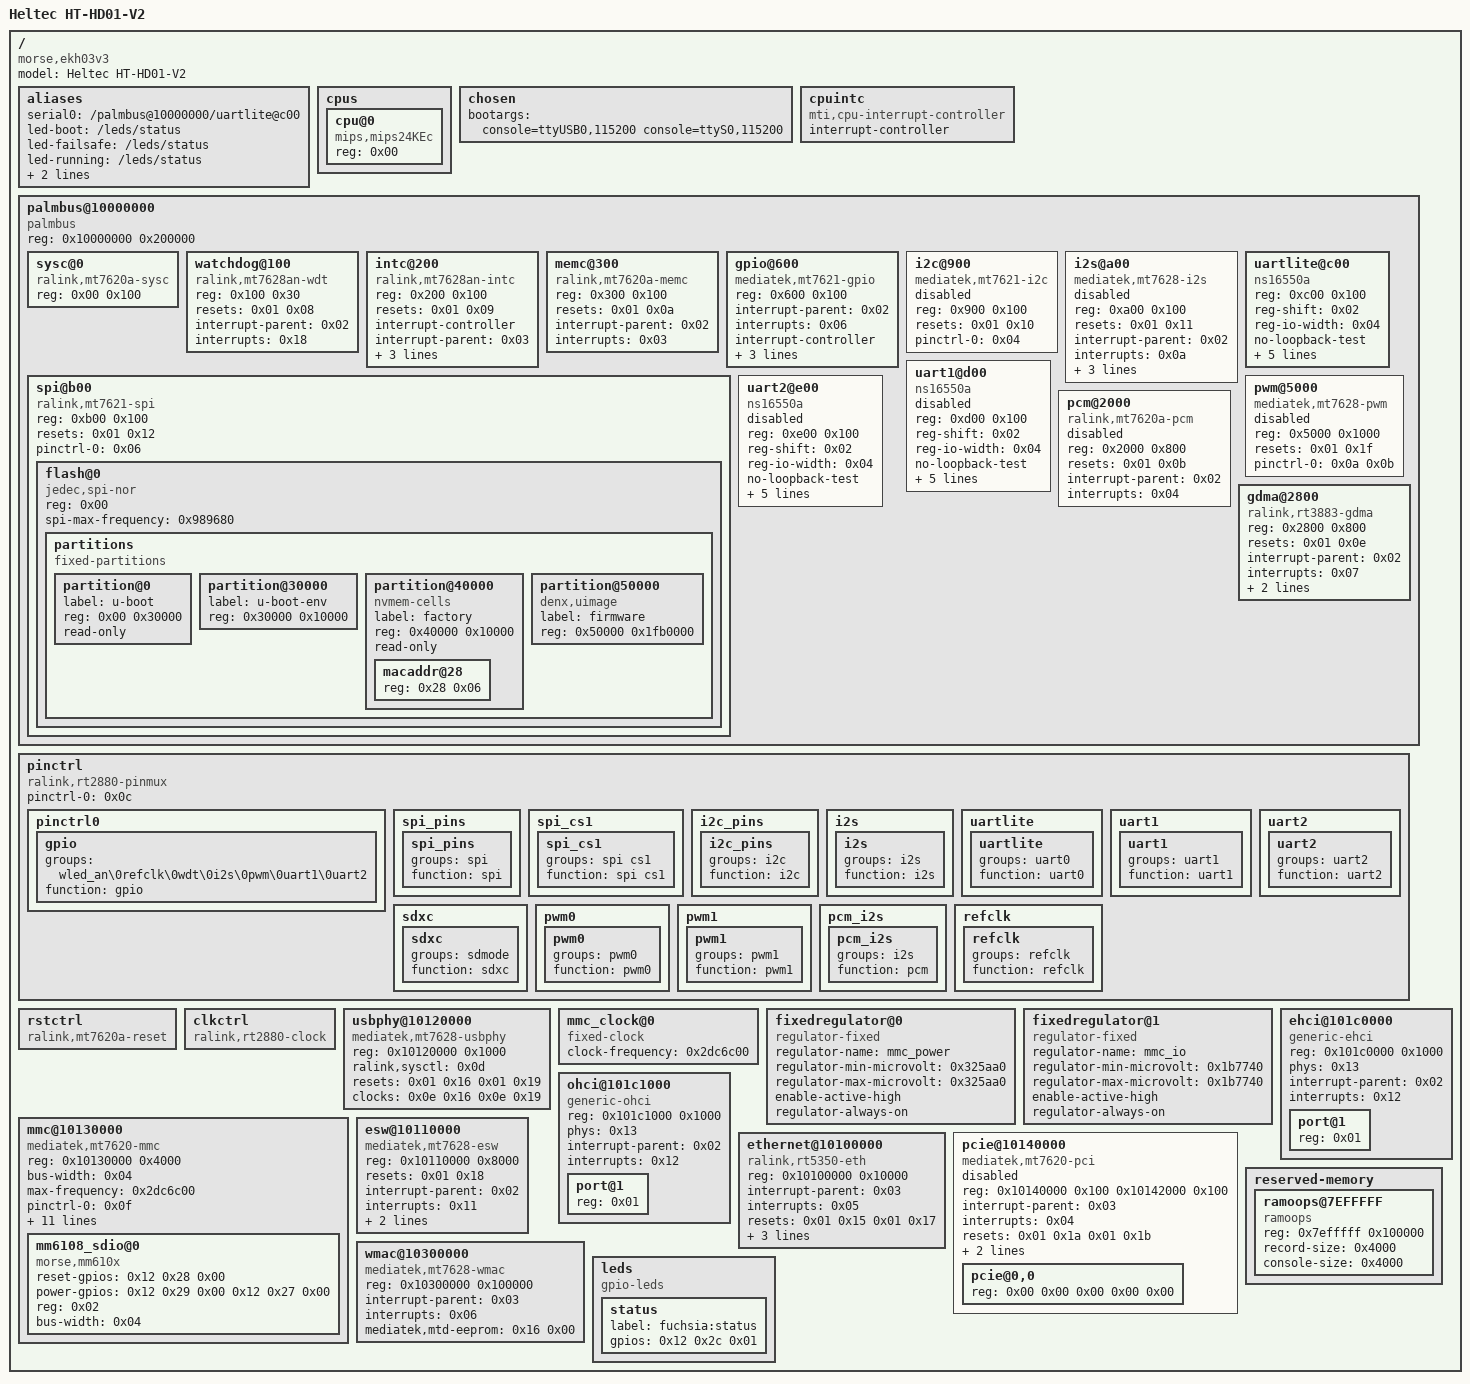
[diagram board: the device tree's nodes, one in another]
/dts-v1/;

/ {
	#address-cells = <0x01>;
	#size-cells = <0x01>;
	compatible = "morse,ekh03v3\0mediatek,mt7628an-soc";
	model = "Heltec HT-HD01-V2";

	aliases {
		serial0 = "/palmbus@10000000/uartlite@c00";
		led-boot = "/leds/status";
		led-failsafe = "/leds/status";
		led-running = "/leds/status";
		led-upgrade = "/leds/status";
		label-mac-device = "/wmac@10300000";
	};

	cpus {
		#address-cells = <0x01>;
		#size-cells = <0x00>;

		cpu@0 {
			compatible = "mips,mips24KEc";
			reg = <0x00>;
		};
	};

	chosen {
		bootargs = "console=ttyUSB0,115200 console=ttyS0,115200";
	};

	cpuintc {
		#address-cells = <0x00>;
		#interrupt-cells = <0x01>;
		interrupt-controller;
		compatible = "mti,cpu-interrupt-controller";
		phandle = <0x03>;
	};

	palmbus@10000000 {
		compatible = "palmbus";
		reg = <0x10000000 0x200000>;
		ranges = <0x00 0x10000000 0x1fffff>;
		#address-cells = <0x01>;
		#size-cells = <0x01>;

		sysc@0 {
			compatible = "ralink,mt7620a-sysc\0syscon";
			reg = <0x00 0x100>;
			phandle = <0x0d>;
		};

		watchdog@100 {
			compatible = "ralink,mt7628an-wdt\0mediatek,mt7621-wdt";
			reg = <0x100 0x30>;
			resets = <0x01 0x08>;
			reset-names = "wdt";
			interrupt-parent = <0x02>;
			interrupts = <0x18>;
		};

		intc@200 {
			compatible = "ralink,mt7628an-intc\0ralink,rt2880-intc";
			reg = <0x200 0x100>;
			resets = <0x01 0x09>;
			reset-names = "intc";
			interrupt-controller;
			#interrupt-cells = <0x01>;
			interrupt-parent = <0x03>;
			interrupts = <0x02>;
			ralink,intc-registers = <0x9c 0xa0 0x6c 0xa4 0x80 0x78>;
			phandle = <0x02>;
		};

		memc@300 {
			compatible = "ralink,mt7620a-memc\0ralink,rt3050-memc";
			reg = <0x300 0x100>;
			resets = <0x01 0x0a>;
			reset-names = "mc";
			interrupt-parent = <0x02>;
			interrupts = <0x03>;
		};

		gpio@600 {
			compatible = "mediatek,mt7621-gpio";
			reg = <0x600 0x100>;
			interrupt-parent = <0x02>;
			interrupts = <0x06>;
			#interrupt-cells = <0x02>;
			interrupt-controller;
			gpio-controller;
			#gpio-cells = <0x02>;
			gpio-line-names = "I2S_SDI\0I2S_SDO\0I2S_WS\0I2S_CLK\0I2C_SCLK\0I2C_SD\0SPI_CS1\0SPI_CLK\0SPI_MOSI\0SPI_MISO\0SPI_CS0\0\0UART_TXD0\0UART_RXD0\0MDI_TP_P1\0MDI_TN_P1\0MDI_RP_P1\0MDI_RN_P1\0MDI_RP_P2\0MDI_RN_P2\0MDI_TP_P2\0MDI_TN_P2\0MDI_TP_P3\0MDI_TN_P3\0MDI_RP_P3\0MDI_RN_P3\0MDI_RP_P4\0MDI_RN_P4\0MDI_TP_P4\0MDI_TN_P4\0\0\0\0\0\0\0PERST_N\0REF_CLKO\0WDT_RST_N\0MM_BUSY\0MM_RESET\0MM_WAKE\0EPHY_LED1_N_JTDI\0EPHY_LED0_N_JTDO\0WLED_N\0UART_TXD1\0UART_RXD1\0\0\0\0\0\0\0\0\0\0\0\0\0\0\0\0\0\0\0\0\0\0\0\0\0\0\0\0\0\0\0\0\0\0\0\0\0\0\0\0\0\0\0\0\0\0\0\0\0";
			status = "okay";
			phandle = <0x12>;
		};

		i2c@900 {
			compatible = "mediatek,mt7621-i2c";
			reg = <0x900 0x100>;
			resets = <0x01 0x10>;
			reset-names = "i2c";
			#address-cells = <0x01>;
			#size-cells = <0x00>;
			status = "disabled";
			pinctrl-names = "default";
			pinctrl-0 = <0x04>;
		};

		i2s@a00 {
			compatible = "mediatek,mt7628-i2s";
			reg = <0xa00 0x100>;
			resets = <0x01 0x11>;
			reset-names = "i2s";
			interrupt-parent = <0x02>;
			interrupts = <0x0a>;
			txdma-req = <0x02>;
			rxdma-req = <0x03>;
			dmas = <0x05 0x04 0x05 0x06>;
			dma-names = "tx\0rx";
			status = "disabled";
		};

		spi@b00 {
			compatible = "ralink,mt7621-spi";
			reg = <0xb00 0x100>;
			resets = <0x01 0x12>;
			reset-names = "spi";
			#address-cells = <0x01>;
			#size-cells = <0x00>;
			pinctrl-names = "default";
			pinctrl-0 = <0x06>;
			status = "okay";

			flash@0 {
				compatible = "jedec,spi-nor";
				reg = <0x00>;
				spi-max-frequency = <0x989680>;

				partitions {
					compatible = "fixed-partitions";
					#address-cells = <0x01>;
					#size-cells = <0x01>;

					partition@0 {
						label = "u-boot";
						reg = <0x00 0x30000>;
						read-only;
					};

					partition@30000 {
						label = "u-boot-env";
						reg = <0x30000 0x10000>;
					};

					partition@40000 {
						label = "factory";
						reg = <0x40000 0x10000>;
						read-only;
						compatible = "nvmem-cells";
						#address-cells = <0x01>;
						#size-cells = <0x01>;
						phandle = <0x16>;

						macaddr@28 {
							reg = <0x28 0x06>;
							phandle = <0x15>;
						};
					};

					partition@50000 {
						compatible = "denx,uimage";
						label = "firmware";
						reg = <0x50000 0x1fb0000>;
					};
				};
			};
		};

		uartlite@c00 {
			compatible = "ns16550a";
			reg = <0xc00 0x100>;
			reg-shift = <0x02>;
			reg-io-width = <0x04>;
			no-loopback-test;
			clock-frequency = <0x2625a00>;
			resets = <0x01 0x0c>;
			reset-names = "uartl";
			interrupt-parent = <0x02>;
			interrupts = <0x14>;
			pinctrl-names = "default";
			pinctrl-0 = <0x07>;
		};

		uart1@d00 {
			compatible = "ns16550a";
			reg = <0xd00 0x100>;
			reg-shift = <0x02>;
			reg-io-width = <0x04>;
			no-loopback-test;
			clock-frequency = <0x2625a00>;
			resets = <0x01 0x13>;
			reset-names = "uart1";
			interrupt-parent = <0x02>;
			interrupts = <0x15>;
			pinctrl-names = "default";
			pinctrl-0 = <0x08>;
			status = "disabled";
		};

		uart2@e00 {
			compatible = "ns16550a";
			reg = <0xe00 0x100>;
			reg-shift = <0x02>;
			reg-io-width = <0x04>;
			no-loopback-test;
			clock-frequency = <0x2625a00>;
			resets = <0x01 0x14>;
			reset-names = "uart2";
			interrupt-parent = <0x02>;
			interrupts = <0x16>;
			pinctrl-names = "default";
			pinctrl-0 = <0x09>;
			status = "disabled";
		};

		pwm@5000 {
			compatible = "mediatek,mt7628-pwm";
			reg = <0x5000 0x1000>;
			#pwm-cells = <0x02>;
			resets = <0x01 0x1f>;
			reset-names = "pwm";
			pinctrl-names = "default";
			pinctrl-0 = <0x0a 0x0b>;
			status = "disabled";
		};

		pcm@2000 {
			compatible = "ralink,mt7620a-pcm";
			reg = <0x2000 0x800>;
			resets = <0x01 0x0b>;
			reset-names = "pcm";
			interrupt-parent = <0x02>;
			interrupts = <0x04>;
			status = "disabled";
		};

		gdma@2800 {
			compatible = "ralink,rt3883-gdma";
			reg = <0x2800 0x800>;
			resets = <0x01 0x0e>;
			reset-names = "dma";
			interrupt-parent = <0x02>;
			interrupts = <0x07>;
			#dma-cells = <0x01>;
			#dma-channels = <0x10>;
			#dma-requests = <0x10>;
			status = "okay";
			phandle = <0x05>;
		};
	};

	pinctrl {
		compatible = "ralink,rt2880-pinmux";
		pinctrl-names = "default";
		pinctrl-0 = <0x0c>;

		pinctrl0 {
			phandle = <0x0c>;

			gpio {
				groups = "wled_an\0refclk\0wdt\0i2s\0pwm\0uart1\0uart2";
				function = "gpio";
			};
		};

		spi_pins {
			phandle = <0x06>;

			spi_pins {
				groups = "spi";
				function = "spi";
			};
		};

		spi_cs1 {

			spi_cs1 {
				groups = "spi cs1";
				function = "spi cs1";
			};
		};

		i2c_pins {
			phandle = <0x04>;

			i2c_pins {
				groups = "i2c";
				function = "i2c";
			};
		};

		i2s {

			i2s {
				groups = "i2s";
				function = "i2s";
			};
		};

		uartlite {
			phandle = <0x07>;

			uartlite {
				groups = "uart0";
				function = "uart0";
			};
		};

		uart1 {
			phandle = <0x08>;

			uart1 {
				groups = "uart1";
				function = "uart1";
			};
		};

		uart2 {
			phandle = <0x09>;

			uart2 {
				groups = "uart2";
				function = "uart2";
			};
		};

		sdxc {
			phandle = <0x0f>;

			sdxc {
				groups = "sdmode";
				function = "sdxc";
			};
		};

		pwm0 {
			phandle = <0x0a>;

			pwm0 {
				groups = "pwm0";
				function = "pwm0";
			};
		};

		pwm1 {
			phandle = <0x0b>;

			pwm1 {
				groups = "pwm1";
				function = "pwm1";
			};
		};

		pcm_i2s {

			pcm_i2s {
				groups = "i2s";
				function = "pcm";
			};
		};

		refclk {

			refclk {
				groups = "refclk";
				function = "refclk";
			};
		};
	};

	rstctrl {
		compatible = "ralink,mt7620a-reset\0ralink,rt2880-reset";
		#reset-cells = <0x01>;
		phandle = <0x01>;
	};

	clkctrl {
		compatible = "ralink,rt2880-clock";
		#clock-cells = <0x01>;
		phandle = <0x0e>;
	};

	usbphy@10120000 {
		compatible = "mediatek,mt7628-usbphy\0mediatek,mt7620-usbphy";
		reg = <0x10120000 0x1000>;
		#phy-cells = <0x00>;
		ralink,sysctl = <0x0d>;
		resets = <0x01 0x16 0x01 0x19>;
		reset-names = "host\0device";
		clocks = <0x0e 0x16 0x0e 0x19>;
		clock-names = "host\0device";
		phandle = <0x13>;
	};

	mmc_clock@0 {
		#clock-cells = <0x00>;
		compatible = "fixed-clock";
		clock-frequency = <0x2dc6c00>;
		phandle = <0x10>;
	};

	fixedregulator@0 {
		compatible = "regulator-fixed";
		regulator-name = "mmc_power";
		regulator-min-microvolt = <0x325aa0>;
		regulator-max-microvolt = <0x325aa0>;
		enable-active-high;
		regulator-always-on;
		phandle = <0x11>;
	};

	fixedregulator@1 {
		compatible = "regulator-fixed";
		regulator-name = "mmc_io";
		regulator-min-microvolt = <0x1b7740>;
		regulator-max-microvolt = <0x1b7740>;
		enable-active-high;
		regulator-always-on;
	};

	mmc@10130000 {
		compatible = "mediatek,mt7620-mmc";
		reg = <0x10130000 0x4000>;
		bus-width = <0x04>;
		max-frequency = <0x2dc6c00>;
		pinctrl-names = "default\0state_uhs";
		pinctrl-0 = <0x0f>;
		pinctrl-1 = <0x0f>;
		clocks = <0x10 0x10>;
		clock-names = "source\0hclk";
		interrupt-parent = <0x02>;
		interrupts = <0x0e>;
		status = "okay";
		cap-sd-highspeed;
		cap-mmc-highspeed;
		vmmc-supply = <0x11>;
		vqmmc-supply = <0x11>;
		cap-sdio-irq;
		non-removable;
		disable-wp;

		mm6108_sdio@0 {
			compatible = "morse,mm610x";
			reset-gpios = <0x12 0x28 0x00>;
			power-gpios = <0x12 0x29 0x00 0x12 0x27 0x00>;
			status = "okay";
			reg = <0x02>;
			bus-width = <0x04>;
		};
	};

	ehci@101c0000 {
		#address-cells = <0x01>;
		#size-cells = <0x00>;
		compatible = "generic-ehci";
		reg = <0x101c0000 0x1000>;
		phys = <0x13>;
		phy-names = "usb";
		interrupt-parent = <0x02>;
		interrupts = <0x12>;

		port@1 {
			reg = <0x01>;
			#trigger-source-cells = <0x00>;
		};
	};

	ohci@101c1000 {
		#address-cells = <0x01>;
		#size-cells = <0x00>;
		compatible = "generic-ohci";
		reg = <0x101c1000 0x1000>;
		phys = <0x13>;
		phy-names = "usb";
		interrupt-parent = <0x02>;
		interrupts = <0x12>;

		port@1 {
			reg = <0x01>;
			#trigger-source-cells = <0x00>;
		};
	};

	ethernet@10100000 {
		compatible = "ralink,rt5350-eth";
		reg = <0x10100000 0x10000>;
		interrupt-parent = <0x03>;
		interrupts = <0x05>;
		resets = <0x01 0x15 0x01 0x17>;
		reset-names = "fe\0esw";
		mediatek,switch = <0x14>;
		nvmem-cells = <0x15>;
		nvmem-cell-names = "mac-address";
	};

	esw@10110000 {
		compatible = "mediatek,mt7628-esw\0ralink,rt3050-esw";
		reg = <0x10110000 0x8000>;
		resets = <0x01 0x18>;
		reset-names = "ephy";
		interrupt-parent = <0x02>;
		interrupts = <0x11>;
		mediatek,portmap = <0x07>;
		mediatek,portdisable = <0x3a>;
		phandle = <0x14>;
	};

	pcie@10140000 {
		compatible = "mediatek,mt7620-pci";
		reg = <0x10140000 0x100 0x10142000 0x100>;
		#address-cells = <0x03>;
		#size-cells = <0x02>;
		interrupt-parent = <0x03>;
		interrupts = <0x04>;
		resets = <0x01 0x1a 0x01 0x1b>;
		reset-names = "pcie0\0pcie1";
		clocks = <0x0e 0x1a 0x0e 0x1b>;
		clock-names = "pcie0\0pcie1";
		status = "disabled";
		device_type = "pci";
		bus-range = <0x00 0xff>;
		ranges = <0x2000000 0x00 0x00 0x20000000 0x00 0x10000000 0x1000000 0x00 0x00 0x10160000 0x00 0x10000>;

		pcie@0,0 {
			reg = <0x00 0x00 0x00 0x00 0x00>;
			#address-cells = <0x03>;
			#size-cells = <0x02>;
			device_type = "pci";
			ranges;
		};
	};

	wmac@10300000 {
		compatible = "mediatek,mt7628-wmac";
		reg = <0x10300000 0x100000>;
		interrupt-parent = <0x03>;
		interrupts = <0x06>;
		status = "okay";
		mediatek,mtd-eeprom = <0x16 0x00>;
	};

	reserved-memory {
		#address-cells = <0x01>;
		#size-cells = <0x01>;
		ranges;

		ramoops@7EFFFFF {
			compatible = "ramoops";
			reg = <0x7efffff 0x100000>;
			record-size = <0x4000>;
			console-size = <0x4000>;
		};
	};

	leds {
		compatible = "gpio-leds";

		status {
			label = "fuchsia:status";
			gpios = <0x12 0x2c 0x01>;
		};
	};
};
